# ATmega128RFA1 device description
Architecture: AVR8; Family: megaAVR
Registers are 8-bit, access not given, no defined reset value unless marked. A register's access mark holds for its fields unless they carry their own. Offsets are from the block's base; [hi:lo] are bit positions.

## FUSE — Fuses
Instances: FUSE 0 in fuses
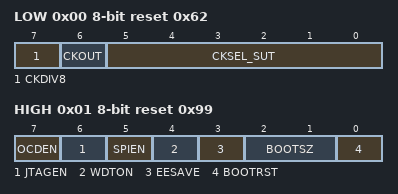
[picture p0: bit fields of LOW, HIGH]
0x00 LOW reset 0x62
  [7] CKDIV8 — Divide clock by 8 internally
  [6] CKOUT — Clock output on PORTE7
  [5:0] CKSEL_SUT — Select Clock Source : Start-up time
    0=EXTCLK_6CK_0MS (Ext. Clock; Start-up time: 6 CK + 0 ms); 16=EXTCLK_6CK_4MS1 (Ext. Clock; Start-up time: 6 CK + 4.1 ms); 32=EXTCLK_6CK_65MS (Ext. Clock; Start-up time: 6 CK + 65 ms); 2=INTRCOSC_6CK_0MS (Int. RC Osc.; Start-up time: 6 CK + 0 ms); 18=INTRCOSC_6CK_4MS1 (Int. RC Osc.; Start-up time: 6 CK + 4.1 ms); 34=INTRCOSC_6CK_65MS (Int. RC Osc.; Start-up time: 6 CK + 65 ms); 3=INTRCOSC_128KHZ_6CK_0MS (Int. 128kHz RC Osc.; Start-up time: 6 CK + 0 ms); 19=INTRCOSC_128KHZ_6CK_4MS1 (Int. 128kHz RC Osc.; Start-up time: 6 CK + 4.1 ms); 35=INTRCOSC_128KHZ_6CK_65MS (Int. 128kHz RC Osc.; Start-up time: 6 CK + 65 ms); 6=TRXOSC_258CK_4MS1 (Tranceiver Oscillator; Start-up time: 258 CK + 4.1 ms); 22=TRXOSC_258CK_65MS (Tranceiver Oscillator; Start-up time: 258 CK + 65 ms); 38=TRXOSC_1KCK_0MS (Tranceiver Oscillator; Start-up time: 1K CK + 0 ms); 54=TRXOSC_1KCK_4MS1 (Tranceiver Oscillator; Start-up time: 1K CK + 4.1 ms); 7=TRXOSC_1KCK_65MS (Tranceiver Oscillator; Start-up time: 1K CK + 65 ms); 23=TRXOSC_16KCK_0MS (Tranceiver Oscillator; Start-up time: 16K CK + 0 ms); 39=TRXOSC_16KCK_4MS1 (Tranceiver Oscillator; Start-up time: 16K CK + 4.1 ms); 55=TRXOSC_16KCK_65MS (Tranceiver Oscillator; Start-up time: 16K CK + 65 ms)
0x01 HIGH reset 0x99
  [7] OCDEN — On-Chip Debug Enabled
  [6] JTAGEN — JTAG Interface Enabled
  [5] SPIEN — Serial program downloading (SPI) enabled
  [4] WDTON — Watchdog timer always on
  [3] EESAVE — Preserve EEPROM through the Chip Erase cycle
  [2:1] BOOTSZ — Select Boot Size
    3=512W_FE00 (Boot Flash size=512 words start address=$FE00); 2=1024W_FC00 (Boot Flash size=1024 words start address=$FC00); 1=2048W_F800 (Boot Flash size=2048 words start address=$F800); 0=4096W_F000 (Boot Flash size=4096 words start address=$F000)
  [0] BOOTRST — Boot Reset vector Enabled
0x02 EXTENDED reset 0xFF
  [2:0] BODLEVEL — Brown-out Detector trigger level
    7=DISABLED (Brown-out detection disabled); 6=1V8 (Brown-out detection at VCC=1.8 V); 5=1V9 (Brown-out detection at VCC=1.9 V); 4=2V0 (Brown-out detection at VCC=2.0 V); 3=2V1 (Brown-out detection at VCC=2.1 V); 2=2V2 (Brown-out detection at VCC=2.2 V); 1=2V3 (Brown-out detection at VCC=2.3 V); 0=2V4 (Brown-out detection at VCC=2.4 V)

## LOCKBIT — Lockbits
Instances: LOCKBIT 0 in lockbits
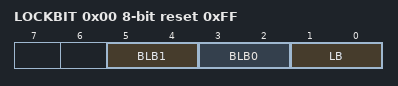
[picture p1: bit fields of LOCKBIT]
0x00 LOCKBIT reset 0xFF
  [5:4] BLB1 — Boot Loader Protection Mode
    0=LPM_SPM_DISABLE (LPM and SPM prohibited in Boot Section); 1=LPM_DISABLE (LPM prohibited in Boot Section); 2=SPM_DISABLE (SPM prohibited in Boot Section); 3=NO_LOCK (No lock on SPM and LPM in Boot Section)
  [3:2] BLB0 — Boot Loader Protection Mode
    0=LPM_SPM_DISABLE (LPM and SPM prohibited in Application Section); 1=LPM_DISABLE (LPM prohibited in Application Section); 2=SPM_DISABLE (SPM prohibited in Application Section); 3=NO_LOCK (No lock on SPM and LPM in Application Section)
  [1:0] LB — Memory Lock
    0=PROG_VER_DISABLED (Further programming and verification disabled); 2=PROG_DISABLED (Further programming disabled); 3=NO_LOCK (No memory lock features enabled)

## AC — Analog Comparator
Instances: AC 0x00
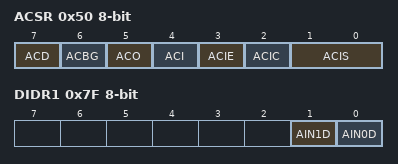
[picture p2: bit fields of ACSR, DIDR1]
0x50 ACSR — Analog Comparator Control And Status Register
  [7] ACD — Analog Comparator Disable
  [6] ACBG — Analog Comparator Bandgap Select
  [5] ACO — Analog Compare Output
  [4] ACI — Analog Comparator Interrupt Flag
  [3] ACIE — Analog Comparator Interrupt Enable
  [2] ACIC — Analog Comparator Input Capture Enable
  [1:0] ACIS — Analog Comparator Interrupt Mode Select
    0=Interrupt on Toggle; 2=Interrupt on Falling Edge; 3=Interrupt on Rising Edge
0x7B ADCSRB — ADC Control and Status Register B
  [6] ACME — Analog Comparator Multiplexer Enable
0x7F DIDR1 — Digital Input Disable Register 1
  [1] AIN1D — AIN1 Digital Input Disable
  [0] AIN0D — AIN0 Digital Input Disable
